# GD32L23x register map
File version: 1.0
CPU: CM23 r0p0, little endian, MPU, FPU, 4 interrupt priority bits
Registers are 32-bit, read-write, reset 0x0 unless marked. A register's access mark holds for its fields unless they carry their own. Offsets are from the block's base; [hi:lo] are bit positions; {n}, {i} and the like mark numbered series.

## CTC — Clock trim controller
Base 0x4000C800
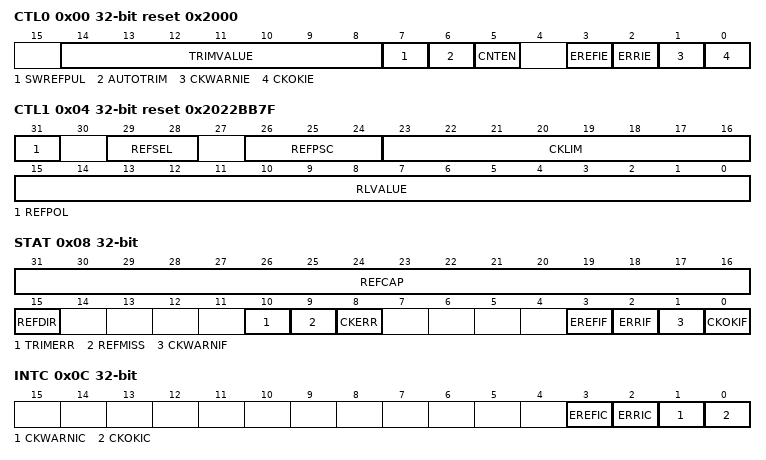
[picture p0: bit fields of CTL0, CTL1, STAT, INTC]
0x00 CTL0 reset 0x2000 — Control register 0
  [14:8] TRIMVALUE — IRC48M trim value
  [7] SWREFPUL — Software reference source sync pulse
  [6] AUTOTRIM — Hardware automatically trim mode
  [5] CNTEN — CTC counter enable
  [3] EREFIE — EREFIF interrupt enable
  [2] ERRIE — Error interrupt enable
  [1] CKWARNIE — Clock trim warning interrupt enable
  [0] CKOKIE — Clock trim ok interrupt enable
0x04 CTL1 reset 0x2022BB7F — Control register 1
  [31] REFPOL — Reference signal source polarity
  [29:28] REFSEL — Reference signal source selection
  [26:24] REFPSC — Reference signal source prescaler
  [23:16] CKLIM — Clock trim base limit value
  [15:0] RLVALUE — CTC counter reload value
0x08 STAT ro — Status register
  [31:16] REFCAP — CTC counter capture when reference sync pulse
  [15] REFDIR — CTC trim counter direction when reference sync pulse
  [10] TRIMERR — Trim value error bit
  [9] REFMISS — Reference sync pulse miss
  [8] CKERR — Clock trim error bit
  [3] EREFIF — Expect reference interrupt flag
  [2] ERRIF — Error interrupt flag
  [1] CKWARNIF — Clock trim warning interrupt flag
  [0] CKOKIF — Clock trim OK interrupt flag
0x0C INTC wo — Interrupt clear register
  [3] EREFIC — EREFIF interrupt clear bit
  [2] ERRIC — ERRIF interrupt clear bit
  [1] CKWARNIC — CKWARNIF interrupt clear bit
  [0] CKOKIC — CKOKIF interrupt clear bit

## DBGMCU — Debug support
Base 0x40015800
0x00 ID ro — MCU Device ID Code Register
  [31:0] ID_CODE — DBG ID code register
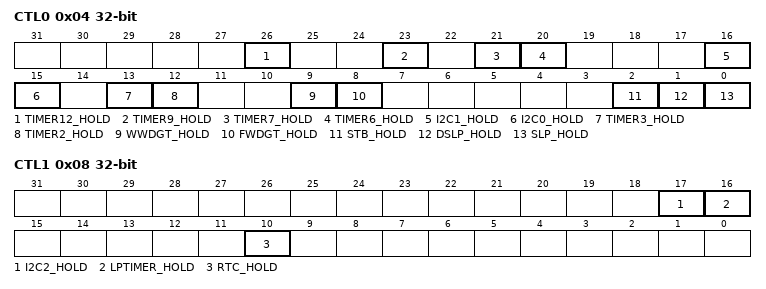
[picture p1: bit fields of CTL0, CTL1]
0x04 CTL0 — Debug Control Register 0
  [26] TIMER12_HOLD
  [23] TIMER9_HOLD
  [21] TIMER7_HOLD
  [20] TIMER6_HOLD
  [16] I2C1_HOLD
  [15] I2C0_HOLD
  [13] TIMER3_HOLD
  [12] TIMER2_HOLD
  [9] WWDGT_HOLD
  [8] FWDGT_HOLD
  [2] STB_HOLD — Standby mode hold Mode
  [1] DSLP_HOLD — DEEPSLEEP mode hold Mode
  [0] SLP_HOLD — Sleep mode hold register
0x08 CTL1 — Debug Control Register 1
  [17] I2C2_HOLD, [16] LPTIMER_HOLD, [10] RTC_HOLD

## DMA — DMA controller
Base 0x40020000
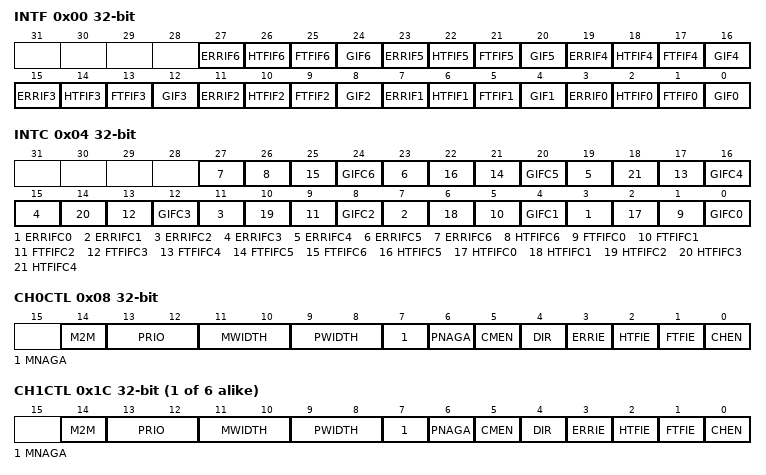
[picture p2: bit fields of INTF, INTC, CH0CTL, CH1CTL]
0x00 INTF ro — DMA interrupt flag register (DMA_INTF)
  [4n+3] ERRIF{n} (n=0..6) — Channel {n} Error flag
  [4n+2] HTFIF{n} (n=0..6) — Channel {n} Half Transfer Finish flag
  [4n+1] FTFIF{n} (n=0..6) — Channel {n} Full Transfer Finish flag
  [4n] GIF{n} (n=0..6) — Channel {n} Global interrupt flag
0x04 INTC wo — DMA interrupt flag clear register (DMA_INTC)
  [4n+3] ERRIFC{n} (n=0..6) — Channel {n} Error clear
  [26] HTFIFC6 — Channel 4 Half Transfer clear
  [4n+1] FTFIFC{n} (n=0..6) — Channel {n} Full Transfer Finish clear
  [4n] GIFC{n} (n=0..6) — Channel {n} Global interrupt flag clear
  [22] HTFIFC5 — Channel 4 Half Transfer clear
  [4n+2] HTFIFC{n} (n=0..4) — Channel {n} Half Transfer clear
0x08 CH0CTL — DMA channel configuration register (DMA_CH0CTL)
  [14] M2M — Memory to memory mode
  [13:12] PRIO — Priority Level of this channel
  [11:10] MWIDTH — Transfer data size of memory
  [9:8] PWIDTH — Transfer data size of peripheral
  [7] MNAGA — Next address generation algorithm of memory
  [6] PNAGA — Next address generation algorithm of peripheral
  [5] CMEN — Circular mode enable
  [4] DIR — Transfer direction
  [3] ERRIE — Transfer access error interrupt enable
  [2] HTFIE — Half Transfer Finish interrupt enable
  [1] FTFIE — Full Transfer Finish interrupt enable
  [0] CHEN — Channel enable
{0xC+0x14*i} CH{i}CNT (i=0..6) — DMA channel {i} counter register
  [15:0] CNT — Transfer counter
{0x10+0x14*i} CH{i}PADDR (i=0..6) — DMA channel {i} peripheral base address register
  [31:0] PADDR — Peripheral base address
{0x14+0x14*i} CH{i}MADDR (i=0..6) — DMA channel {i} memory base address register
  [31:0] MADDR — Memory address
{0x8+0x14*i} CH{i}CTL (i=1..6) — DMA channel configuration register (DMA_CH{i}CTL)
  [14] M2M — Memory to memory mode
  [13:12] PRIO — Priority Level of this channel
  [11:10] MWIDTH — Transfer data size of memory
  [9:8] PWIDTH — Transfer data size of peripheral
  [7] MNAGA — Next address generation algorithm of memory
  [6] PNAGA — Next address generation algorithm of peripheral
  [5] CMEN — Circular mode enable
  [4] DIR — Transfer direction
  [3] ERRIE — Error interrupt enable
  [2] HTFIE — Half Transfer Finish interrupt enable
  [1] FTFIE — Full Transfer Finish interrupt enable
  [0] CHEN — Channel enable
